# nrf52 register map
Vendor: Nordic Semiconductor; Series: nrf52; File version: 1
CPU: CM4 r0p1, little endian, MPU, FPU, 3 interrupt priority bits
Registers are 32-bit, read-write, reset 0x0 unless marked. A register's access mark holds for its fields unless they carry their own. Offsets are from the block's base; [hi:lo] are bit positions; lines under a group give offsets from that group; {n}, {i} and the like mark numbered series; 'fields as' and 'values as' point back to an identical list.

## SPI0 — Serial Peripheral Interface 0
Base 0x40003000
Same registers: SPI1 0x40004000, SPI2 0x40023000
0x108 EVENTS_READY — TXD byte sent and RXD byte received
  [0] EVENTS_READY
    0=NotGenerated (Event not generated); 1=Generated (Event generated)
0x304 INTENSET — Enable interrupt
  [2] READY — Write '1' to enable interrupt for event READY
    on read: 0=Disabled (Read: Disabled); 1=Enabled (Read: Enabled) | on write: 1=Set (Enable)
0x308 INTENCLR — Disable interrupt
  [2] READY — Write '1' to disable interrupt for event READY
    on read: 0=Disabled (Read: Disabled); 1=Enabled (Read: Enabled) | on write: 1=Clear (Disable)
0x500 ENABLE — Enable SPI
  [3:0] ENABLE — Enable or disable SPI
    0=Disabled (Disable SPI); 1=Enabled (Enable SPI)
0x508 PSEL group — Unspecified
  0x00 SCK reset 0xFFFFFFFF — Pin select for SCK
    [31:0] PSELSCK — Pin number configuration for SPI SCK signal
      0xFFFFFFFF=Disconnected
  0x04 MOSI reset 0xFFFFFFFF — Pin select for MOSI
    [31:0] PSELMOSI — Pin number configuration for SPI MOSI signal
      0xFFFFFFFF=Disconnected
  0x08 MISO reset 0xFFFFFFFF — Pin select for MISO
    [31:0] PSELMISO — Pin number configuration for SPI MISO signal
      0xFFFFFFFF=Disconnected
0x518 RXD ro
  [7:0] RXD — RX data received. Double buffered
0x51C TXD
  [7:0] TXD — TX data to send. Double buffered
0x524 FREQUENCY reset 0x4000000 — SPI frequency
  [31:0] FREQUENCY — SPI master data rate
    0x2000000=K125 (125 kbps); 0x4000000=K250 (250 kbps); 0x8000000=K500 (500 kbps); 0x10000000=M1 (1 Mbps); 0x20000000=M2 (2 Mbps); 0x40000000=M4 (4 Mbps); 0x80000000=M8 (8 Mbps)
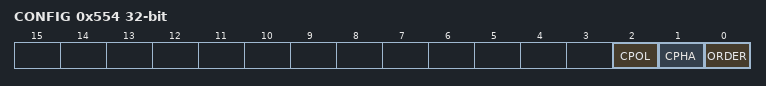
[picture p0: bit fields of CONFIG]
0x554 CONFIG — Configuration register
  [2] CPOL — Serial clock (SCK) polarity
    0=ActiveHigh; 1=ActiveLow
  [1] CPHA — Serial clock (SCK) phase
    0=Leading (Sample on leading edge of clock, shift serial data on trailing edge); 1=Trailing (Sample on trailing edge of clock, shift serial data on leading edge)
  [0] ORDER — Bit order
    0=MsbFirst (Most significant bit shifted out first); 1=LsbFirst (Least significant bit shifted out first)

## GPIOTE — GPIO Tasks and Events
Base 0x40006000
{0x0+4i} TASKS_OUT[{i}] (i=0..7) wo — Description collection: Task for writing to pin specified in CONFIG[n].PSEL. Action on pin is configured in CONFIG[n].POLARITY.
  [0] TASKS_OUT — Task for writing to pin specified in CONFIG[n].PSEL. Action on pin is configured in CONFIG[n].POLARITY.
    1=Trigger task
{0x30+4i} TASKS_SET[{i}] (i=0..7) wo — Description collection: Task for writing to pin specified in CONFIG[n].PSEL. Action on pin is to set it high.
  [0] TASKS_SET — Task for writing to pin specified in CONFIG[n].PSEL. Action on pin is to set it high.
    1=Trigger task
{0x60+4i} TASKS_CLR[{i}] (i=0..7) wo — Description collection: Task for writing to pin specified in CONFIG[n].PSEL. Action on pin is to set it low.
  [0] TASKS_CLR — Task for writing to pin specified in CONFIG[n].PSEL. Action on pin is to set it low.
    1=Trigger task
{0x100+4i} EVENTS_IN[{i}] (i=0..7) — Description collection: Event generated from pin specified in CONFIG[n].PSEL
  [0] EVENTS_IN — Event generated from pin specified in CONFIG[n].PSEL
    0=NotGenerated (Event not generated); 1=Generated (Event generated)
0x17C EVENTS_PORT — Event generated from multiple input GPIO pins with SENSE mechanism enabled
  [0] EVENTS_PORT
    values as EVENTS_IN[0].EVENTS_IN
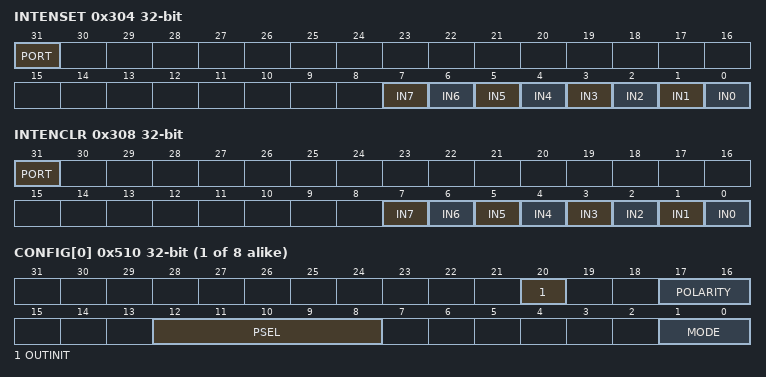
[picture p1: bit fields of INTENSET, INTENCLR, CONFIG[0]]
0x304 INTENSET — Enable interrupt
  [all] fields
    on read: 0=Disabled (Read: Disabled); 1=Enabled (Read: Enabled) | on write: 1=Set (Enable)
  [31] PORT — Write '1' to enable interrupt for event PORT
  [n] IN{n} (n=0..7) — Write '1' to enable interrupt for event IN[{n}]
0x308 INTENCLR — Disable interrupt
  [all] fields
    on read: 0=Disabled (Read: Disabled); 1=Enabled (Read: Enabled) | on write: 1=Clear (Disable)
  [31] PORT — Write '1' to disable interrupt for event PORT
  [n] IN{n} (n=0..7) — Write '1' to disable interrupt for event IN[{n}]
{0x510+4i} CONFIG[{i}] (i=0..7) — Description collection: Configuration for OUT[n], SET[n] and CLR[n] tasks and IN[n] event
  [20] OUTINIT — When in task mode: Initial value of the output when the GPIOTE channel is configured. When in event mode: No effect.
    0=Low (Task mode: Initial value of pin before task triggering is low); 1=High (Task mode: Initial value of pin before task triggering is high)
  [17:16] POLARITY — When In task mode: Operation to be performed on output when OUT[n] task is triggered. When In event mode: Operation on input that shall trigger IN[n] event.
    0=None (Task mode: No effect on pin from OUT[n] task. Event mode: no IN[n] event generated on pin activity.); 1=LoToHi (Task mode: Set pin from OUT[n] task. Event mode: Generate IN[n] event when rising edge on pin.); 2=HiToLo (Task mode: Clear pin from OUT[n] task. Event mode: Generate IN[n] event when falling edge on pin.); 3=Toggle (Task mode: Toggle pin from OUT[n]. Event mode: Generate IN[n] when any change on pin.)
  [12:8] PSEL — GPIO number associated with SET[n], CLR[n] and OUT[n] tasks and IN[n] event
  [1:0] MODE
    0=Disabled. Pin specified by PSEL will not be acquired by the GPIOTE module.; 1=Event mode; 3=Task mode
